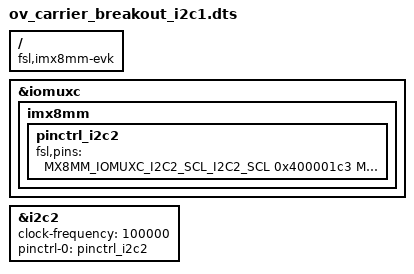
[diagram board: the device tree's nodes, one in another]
/**
 * Portenta-M8 dtb overlay file
 * Arduino 2021
 * Enable I2C1 on Arduino Breakout carrier board
 * Default speed: 100kHz
 */

/dts-v1/;
/plugin/;

#include "imx8mm-pinfunc.h"

/ {
	compatible = "fsl,imx8mm-evk", "fsl,imx8mm";

	fragment@0 {
		target = <&iomuxc>;
		__overlay__ {
			imx8mm {
				pinctrl_i2c2 {
					fsl,pins = <
						MX8MM_IOMUXC_I2C2_SCL_I2C2_SCL      0x400001c3
						MX8MM_IOMUXC_I2C2_SDA_I2C2_SDA      0x400001c3
					>;
				};
			};
		};
	};

	fragment@1 {
		target = <&i2c2>;
		__overlay__ {
			clock-frequency = <100000>;
			pinctrl-names = "default";
			pinctrl-0 = <&pinctrl_i2c2>;
			status = "okay";
		};
	};
};
